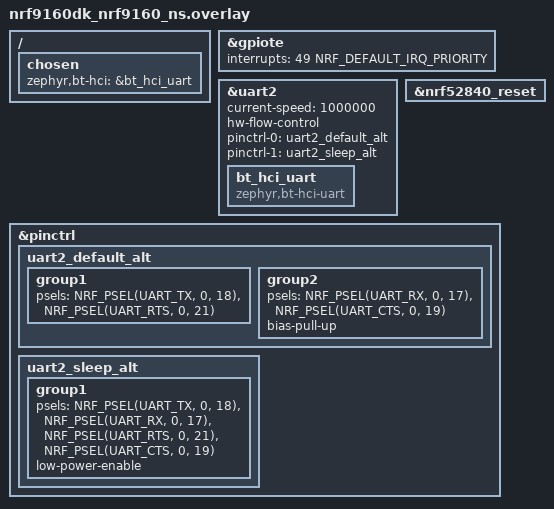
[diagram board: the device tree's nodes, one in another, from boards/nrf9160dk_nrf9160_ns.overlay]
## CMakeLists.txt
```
#
# Copyright (c) 2022 Nordic Semiconductor ASA
#
# SPDX-License-Identifier: LicenseRef-Nordic-5-Clause
#

cmake_minimum_required(VERSION 3.20.0)

find_package(Zephyr REQUIRED HINTS $ENV{ZEPHYR_BASE})
project(nrf_cloud_multi_service)

# Include certs files if enabled.
zephyr_include_directories_ifdef(CONFIG_NRF_CLOUD_PROVISION_CERTIFICATES certs)

# NORDIC SDK APP START
target_sources(app PRIVATE src/main.c)
target_sources(app PRIVATE src/application.c)
target_sources(app PRIVATE src/cloud_connection.c)
target_sources(app PRIVATE src/message_queue.c)
target_sources(app PRIVATE src/temperature.c)
target_sources(app PRIVATE src/fota_support.c)
target_sources(app PRIVATE src/led_control.c)
target_sources(app PRIVATE src/sample_reboot.c)
target_sources(app PRIVATE src/shadow_config.c)

if(CONFIG_LOCATION_TRACKING)
  target_sources(app PRIVATE src/location_tracking.c)
endif()

if(CONFIG_COAP_SHADOW)
  target_sources(app PRIVATE src/shadow_support_coap.c)
endif()

if(CONFIG_COAP_FOTA)
  target_sources(app PRIVATE src/fota_support_coap.c)
endif()

if(CONFIG_NRF_PROVISIONING)
  target_sources(app PRIVATE src/provisioning_support.c)
endif()

# Include modem-specific features if supported
if(CONFIG_NRF_MODEM_LIB)
  target_sources(app PRIVATE src/at_commands.c)
endif()

# NORDIC SDK APP END

zephyr_include_directories(src)
```

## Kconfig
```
#
# Copyright (c) 2022 Nordic Semiconductor ASA
#
# SPDX-License-Identifier: LicenseRef-Nordic-5-Clause
#

menu "Multi Service Sample Settings"

config APP_VERSION
	string "Multi Service Sample version"
	default "1.0.0"

config CLOUD_CONNECTION_RETRY_TIMEOUT_SECONDS
	int "Cloud connection retry timeout (seconds)"
	default 30
	help
	  If connecting to nRF Cloud takes longer than this timeout, it will be
	  reattempted.

config CLOUD_READY_TIMEOUT_SECONDS
	int "Cloud readiness timeout (seconds)"
	default 600
	help
	  If the connection to nRF Cloud does not become ready within this
	  timeout, the sample will reset its connection and try again.

config DATE_TIME_ESTABLISHMENT_TIMEOUT_SECONDS
	int "Modem date and time establishment timeout (seconds)"
	default 300
	help
	  The sample will wait this many seconds for the modem to determine the
	  current date and time before giving up and moving on.

config APPLICATION_THREAD_STACK_SIZE
	int "Application Thread Stack Size (bytes)"
	default 2048
	help
	  Sets the stack size (in bytes) for the application thread of the
	  sample.

config CONNECTION_THREAD_STACK_SIZE
	int "Connection Thread Stack Size (bytes)"
	default 2048
	help
	  Sets the stack size (in bytes) for the connection thread of the
	  sample.

config MESSAGE_THREAD_STACK_SIZE
	int "Message Queue Thread Stack Size (bytes)"
	default 2048
	help
	  Sets the stack size (in bytes) for the message queue processing
	  thread of the sample.

config LED_THREAD_STACK_SIZE
	int "LED Thread Stack Size (bytes)"
	default 1024
	help
	  Sets the stack size (in bytes) for the LED thread.

config MAX_OUTGOING_MESSAGES
	int "Outgoing message maximum"
	default 25
	help
	  Sets the maximum number of device messages which may be enqueued
	  before further messages are dropped.
	  Increasing this value may require an increase to CONFIG_HEAP_MEM_POOL_SIZE.

config MAX_CONSECUTIVE_SEND_FAILURES
	int "Max outgoing consecutive send failures"
	default 5
	help
	  Sets the maximum number of device messages which may fail to send
	  before a connection reset and cooldown is triggered.

config CONSECUTIVE_SEND_FAILURE_COOLDOWN_SECONDS
	int "Cooldown after max consecutive send failures exceeded"
	default 10
	help
	  If a connection reset is triggered by too many failed device
	  messages, the sample will wait this long (in seconds) before trying
	  again.

config SENSOR_SAMPLE_INTERVAL_SECONDS
	int "Sensor sampling interval (seconds)"
	default 60
	help
	  Sets the time to wait between each sensor sample.

menuconfig LOCATION_TRACKING
	bool "Location tracking service"
	default y
	help
	  Uses GNSS, LTE, and/or Wi-Fi information to determine and report device
	  location.

if LOCATION_TRACKING

config LOCATION_TRACKING_SAMPLE_INTERVAL_SECONDS
	int "Location sampling interval (seconds)"
	default 60
	help
	  Sets the location sampling interval in seconds.

config LOCATION_TRACKING_GNSS
	bool "Use GNSS method for location tracking"
	default y
	depends on LOCATION_METHOD_GNSS
	help
	  Disable all location tracking methods to completely disable location tracking.

config LOCATION_TRACKING_CELLULAR
	bool "Use cellular method for location tracking"
	default y
	depends on LOCATION_METHOD_CELLULAR
	help
	  Disable all location tracking methods to completely disable location tracking.

config LOCATION_TRACKING_WIFI
	bool "Use Wi-Fi method for location tracking"
	depends on LOCATION_METHOD_WIFI
	help
	  Requires the use of an nRF7002 companion chip.
	  Disable all location tracking methods to completely disable location tracking.

endif

config TEMP_DATA_USE_SENSOR
	bool "Use genuine temperature data"
	depends on BOARD_THINGY91_NRF9160_NS || BOARD_THINGY91X_NRF9151_NS
	default y if BOARD_THINGY91_NRF9160_NS || BOARD_THINGY91X_NRF9151_NS
	select SENSOR
	select BME680
	help
	  Sets whether to take genuine temperature measurements from a
	  connected BME680 sensor, or just simulate sensor data.

config TEMP_TRACKING
	bool "Track temperature"
	default y
	help
	  Sets whether to take temperature measurements.

config TEMP_ALERT_LIMIT
	int "Temperature limit to print alert"
	default 30
	help
	  Sets the temperature in degrees C over which a temperature alert will
	  be printed through serial terminal.

choice
	prompt "LED indication"
	default LED_INDICATION_PWM if BOARD_THINGY91_NRF9160_NS || BOARD_THINGY91X_NRF9151_NS
	default LED_INDICATION_GPIO if BOARD_NRF9160DK_NRF9160_NS || BOARD_NRF9161DK_NRF9161_NS || $(dt_compat_enabled,gpio-leds)
	default LED_INDICATION_DISABLED

config LED_INDICATION_PWM
	bool "Enable LED indication using the pwm-leds driver"
	select LED
	select LED_PWM
	select PWM

config LED_INDICATION_GPIO
	bool "Enable LED indication using the gpio-leds driver"
	select LED
	select LED_GPIO

config LED_INDICATION_DISABLED
	bool "Disable LED indication"

endchoice

choice
	prompt "LED indication LED type"
	depends on !LED_INDICATION_DISABLED
	default LED_INDICATOR_RGB if (BOARD_THINGY91_NRF9160_NS || BOARD_THINGY91X_NRF9151_NS) && LED_INDICATION_PWM
	default LED_INDICATOR_4LED if !LED_INDICATION_DISABLED
	default LED_INDICATOR_NONE

config LED_INDICATOR_RGB
	bool "A single RGB LED"
	depends on LED_INDICATION_PWM

config LED_INDICATOR_4LED
	bool "Four binary LEDs"
	depends on !LED_INDICATION_DISABLED

config LED_INDICATOR_NONE
	bool "No indicator LEDs"
	depends on LED_INDICATION_DISABLED

endchoice

config LED_VERBOSE_INDICATION
	bool "Enables extra LED status indications"
	depends on !LED_INDICATION_DISABLED
	default y

config LED_CONTINUOUS_INDICATION
	bool "Show an idle pattern instead of turning LEDs off"
	depends on !LED_INDICATION_DISABLED
	default y

config GNSS_FIX_TIMEOUT_SECONDS
	int "GNSS Fix timeout"
	default 40
	help
	  On each location sample, try for this long to achieve a GNSS fix
	  before falling back to cellular positioning.
	  Set this to 20 or so seconds below the sensor sample interval so
	  that there is time left over to perform cellular positioning.
	  Otherwise, location samples may occur at a longer interval than
	  requested.

config TEST_COUNTER
	bool "Sets whether the test counter is enabled"
	help
	  When enabled, the test counter configuration setting in the shadow is ignored.

config TEST_COUNTER_MULTIPLIER
	int "The number of test counter messages sent on each update"
	default 1
	range 1 1000
	help
	  This is a way to increase the number of device messages sent by the sample.
	  It is useful for load testing.

config AT_CMD_REQUESTS
	bool "Enables remote execution of AT commands using device messages"
	depends on !NRF_CLOUD_COAP
	default y

config AT_CMD_REQUEST_RESPONSE_BUFFER_LENGTH
	int "Max length (in bytes) for Modem responses during AT command requests"
	help
	  Responses to modem AT commands are stored in a buffer of this length before being sent to
	  nRF Cloud. If a response from the modem exceeds this length, it will be dropped, and an
	  error code sent in its place (-NRF_E2BIG). Cannot be less than 40 bytes.
	default 200

config POST_PROVISIONING_INTERVAL_M
	int "Delay in minutes between provisioning checks once connected"
	default 30
	help
	  Use a slower rate to check for provisioning after we have successfully connected.
	  Until then use CONFIG_NRF_PROVISIONING_INTERVAL_S.

if NRF_CLOUD_COAP

menuconfig COAP_FOTA
	bool "FOTA service when using CoAP to connect to nRF Cloud"
	select FOTA_DOWNLOAD
	select FOTA_DOWNLOAD_PROGRESS_EVT
	select IMG_ERASE_PROGRESSIVELY
	select DFU_TARGET
	select DOWNLOADER
	select REBOOT
	select CJSON_LIB
	select SETTINGS
	default y

if COAP_FOTA

config COAP_FOTA_JOB_CHECK_RATE_MINUTES
	int "FOTA job check interval (minutes)"
	default 60
	help
	  Sets the time to wait between each request to get any pending FOTA job.

config COAP_FOTA_THREAD_STACK_SIZE
	int "CoAP FOTA Thread Stack Size (bytes)"
	default 2048
	help
	  Sets the stack size (in bytes) for the CoAP FOTA thread of the
	  sample.

endif

menuconfig COAP_SHADOW
	bool "Updating shadow service"
	default y
	help
	  Updates the shadow with device information. Checks for a shadow
	  delta periodically and processes it if received.

if COAP_SHADOW

config COAP_SHADOW_CHECK_RATE_SECONDS
	int "Shadow job check interval (seconds)"
	default 300
	help
	  Sets the time to wait between each request to get any change to the
	  device shadow.

config COAP_SHADOW_THREAD_STACK_SIZE
	int "CoAP Shadow Thread Stack Size (bytes)"
	default 3072
	help
	  Sets the stack size (in bytes) for the CoAP shadow thread of the
	  sample.

endif

config COAP_SEND_CONFIRMABLE
	bool "Send device messages as confirmable"
	help
	  Ensures all CoAP transfers, even for often less important messages such
	  as sensor data, are sent as confirmable messages.

endif

endmenu

if NRF_CLOUD_MQTT
module-str = MQTT Multi Service
endif
if NRF_CLOUD_COAP
module-str = CoAP Multi Service
endif
module = MULTI_SERVICE
source "$(ZEPHYR_BASE)/subsys/logging/Kconfig.template.log_config"

menu "Zephyr Kernel"
source "Kconfig.zephyr"
endmenu
```

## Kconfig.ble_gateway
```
#
# Copyright (c) 2024 Nordic Semiconductor ASA
#
# SPDX-License-Identifier: LicenseRef-Nordic-5-Clause
#

menu "nRF Cloud BLE Gateway Sample Settings"

if NRF_CLOUD_GATEWAY

config USE_BT_HCI_SETUP
	bool "Use BT HCI setup"
	default y
	select BT_HCI_SETUP
	help
	  Get the setup to run.

config APPLICATION_WORKQUEUE_PRIORITY
	int "Application workqueue priority"
	default SYSTEM_WORKQUEUE_PRIORITY

config FLASH_TEST
	bool "Enable Flash Test module"
	default n
	select NRFX_SPIM if FLASH_TEST
	select NRFX_SPIM3 if FLASH_TEST
	select SPI if FLASH_TEST
	select SPI_NOR if FLASH_TEST
	help
	  Enable to test Erase, Write, and Read of external flash.

config CLOUD_BUTTON
	bool "Enable button sensor"
	default y

config CLOUD_BUTTON_INPUT
	int "Set button sensor button number"
	range 1 4 if BOARD_NRF9160_PCA10090NS
	range 1 1 if BOARD_NRF9160_PCA20035NS
	default 1

config ENTER_52840_MCUBOOT_VIA_BUTTON
	bool "Button enables 52840 MCUboot"
	depends on BOARD_APRICITY_GATEWAY_NRF9160 || BOARD_APRICITY_GATEWAY_NRF9160_NS
	help
	  Holding a button during and after startup will place the
	  nrf52840 into MCUboot mode so the firmware can be updated.

config SHELL_PROMPT_SECURE
	string "Displayed prompt name"
	default "uart:~# "
	help
	  Displayed prompt name for UART backend once user has logged in.

config SHELL_DEFAULT_PASSWORD
	string "Factory-set initial password"
	default "nordic"
	help
	  User needs to type this to enter the shell and execute
	  commands.

config GATEWAY_BLE_FOTA
	bool "Enable BLE FOTA support"
	default y
	help
	  Enable ability to receive FOTA jobs for specific BLE devices,
	  then inject data from one or more file downloads to a BLE
	  device that supports a compatible DFU protocol.

config GATEWAY_DBG_CMDS
	bool "Enable debugging commands"
	default y
	select CPU_LOAD
	select CPU_LOAD_CMDS
	select KERNEL_SHELL

config GATEWAY_SHELL
	bool "Enable shell for administering nRF Cloud gateway"
	default y
	select SHELL
	select SHELL_CMDS
	select SHELL_HISTORY
	select SHELL_METAKEYS
	select SHELL_VT100_COLORS
	select SHELL_BACKEND_SERIAL
	select SHELL_CMDS_SELECT

config STARTING_LOG_OVERRIDE
	bool "Different logging level at boot"
	default n
	help
	  All configured logging will occur if disabled. Otherwise,
	  logging changed to STARTING_LOG_LEVEL until user logs in and
	  manually enables with 'log enable inf' (or whatever level is
	  desired).

choice
	prompt "Max compiled-in log level to boot with"
	default STARTING_LOG_LEVEL_INF
	depends on LOG

config STARTING_LOG_LEVEL_OFF
	bool "Off"

config STARTING_LOG_LEVEL_ERR
	bool "Error"

config STARTING_LOG_LEVEL_WRN
	bool "Warning"

config STARTING_LOG_LEVEL_INF
	bool "Info"

config STARTING_LOG_LEVEL_DBG
	bool "Debug"

endchoice

config STARTING_LOG_LEVEL
	int
	depends on LOG
	default 0 if STARTING_LOG_LEVEL_OFF
	default 1 if STARTING_LOG_LEVEL_ERR
	default 2 if STARTING_LOG_LEVEL_WRN
	default 3 if STARTING_LOG_LEVEL_INF
	default 4 if STARTING_LOG_LEVEL_DBG

if NRF_CLOUD_MQTT
module-str = MQTT BLE Gateway
endif
if NRF_CLOUD_COAP
module-str = CoAP BLE Gateway
endif
module = NRFCLOUD_BLE_GATEWAY
source "subsys/logging/Kconfig.template.log_config"

endif

endmenu
```

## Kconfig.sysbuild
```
#
# Copyright (c) 2024 Nordic Semiconductor
#
# SPDX-License-Identifier: LicenseRef-Nordic-5-Clause
#

config WIFI_NRF70
	default y if BOARD_THINGY91X_NRF9151_NS

source "${ZEPHYR_BASE}/share/sysbuild/Kconfig"
```

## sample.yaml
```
sample:
  name: nRF Cloud Multi Service Sample
tests:
  sample.cellular.nrf_cloud_multi_service.mqtt:
    sysbuild: true
    build_only: true
    platform_allow:
      - nrf9151dk/nrf9151/ns
      - nrf9160dk/nrf9160/ns
      - nrf9161dk/nrf9161/ns
      - thingy91/nrf9160/ns
      - thingy91x/nrf9151/ns
    integration_platforms:
      - nrf9151dk/nrf9151/ns
      - nrf9160dk/nrf9160/ns
      - thingy91/nrf9160/ns
      - thingy91x/nrf9151/ns
    tags:
      - ci_build
      - sysbuild
      - ci_samples_cellular
  sample.cellular.nrf_cloud_multi_service.mqtt.full:
    sysbuild: true
    build_only: true
    platform_allow: nrf9160dk/nrf9160/ns
    integration_platforms:
      - nrf9160dk/nrf9160/ns
    extra_args:
      - "EXTRA_CONF_FILE=\"overlay_full_modem_fota.conf;overlay_pgps_ext_flash.conf;overlay_mcuboot_ext_flash.conf\""
    tags:
      - ci_build
      - sysbuild
      - ci_samples_cellular
  sample.cellular.nrf_cloud_multi_service.mqtt.min:
    sysbuild: true
    build_only: true
    platform_allow: nrf9160dk/nrf9160/ns
    integration_platforms:
      - nrf9160dk/nrf9160/ns
    extra_args: EXTRA_CONF_FILE="overlay_min_mqtt.conf"
    tags:
      - ci_build
      - sysbuild
      - ci_samples_cellular
  sample.cellular.nrf_cloud_multi_service.coap:
    sysbuild: true
    build_only: true
    platform_allow:
      - nrf9151dk/nrf9151/ns
      - nrf9160dk/nrf9160/ns
      - nrf9161dk/nrf9161/ns
      - thingy91/nrf9160/ns
      - thingy91x/nrf9151/ns
    integration_platforms:
      - nrf9151dk/nrf9151/ns
      - nrf9160dk/nrf9160/ns
      - nrf9161dk/nrf9161/ns
      - thingy91x/nrf9151/ns
    extra_args: EXTRA_CONF_FILE="overlay_coap.conf"
    tags:
      - ci_build
      - sysbuild
      - ci_samples_cellular
  sample.cellular.nrf_cloud_multi_service.coap.min:
    sysbuild: true
    build_only: true
    platform_allow: nrf9160dk/nrf9160/ns
    integration_platforms:
      - nrf9160dk/nrf9160/ns
    extra_args: EXTRA_CONF_FILE="overlay_coap.conf;overlay_min_coap.conf"
    tags:
      - ci_build
      - sysbuild
      - ci_samples_cellular
  sample.cellular.nrf_cloud_multi_service.coap.trace:
    sysbuild: true
    build_only: true
    platform_allow:
      - nrf9151dk/nrf9151/ns
      - nrf9160dk/nrf9160/ns
      - nrf9161dk/nrf9161/ns
    integration_platforms:
      - nrf9151dk/nrf9151/ns
      - nrf9160dk/nrf9160/ns
      - nrf9161dk/nrf9161/ns
    extra_args:
      - EXTRA_CONF_FILE="overlay-coap_nrf_provisioning.conf;overlay_coap.conf"
      - nrf_cloud_multi_service_SNIPPET=nrf91-modem-trace-uart
    tags:
      - ci_build
      - sysbuild
      - ci_samples_cellular
  sample.cellular.nrf_cloud_multi_service.mqtt.provisioning.trace:
    sysbuild: true
    build_only: true
    platform_allow:
      - nrf9151dk/nrf9151/ns
      - nrf9160dk/nrf9160/ns
      - nrf9161dk/nrf9161/ns
      - thingy91/nrf9160/ns
      - thingy91x/nrf9151/ns
    integration_platforms:
      - nrf9151dk/nrf9151/ns
      - nrf9160dk/nrf9160/ns
      - nrf9161dk/nrf9161/ns
      - thingy91/nrf9160/ns
      - thingy91x/nrf9151/ns
    extra_args:
      - EXTRA_CONF_FILE="overlay-http_nrf_provisioning.conf"
      - nrf_cloud_multi_service_SNIPPET=nrf91-modem-trace-uart
    tags:
      - ci_build
      - sysbuild
      - ci_samples_cellular
  sample.cellular.nrf7002ek_wifi.scan:
    sysbuild: true
    build_only: true
    integration_platforms:
      - nrf9151dk/nrf9151/ns
      - nrf9161dk/nrf9161/ns
    platform_allow:
      - nrf9151dk/nrf9151/ns
      - nrf9160dk/nrf9160/ns
      - nrf9161dk/nrf9161/ns
    extra_args:
      - nrf_cloud_multi_service_SHIELD=nrf7002ek_nrf7000
      - EXTRA_CONF_FILE="overlay-nrf7002ek-wifi-scan-only.conf"
      - SB_CONF_FILE="sysbuild_nrf700x-wifi-scan.conf"
    tags:
      - ci_build
      - sysbuild
      - ci_samples_cellular
  sample.cellular.nrf7002ek_wifi.conn:
    sysbuild: true
    build_only: true
    integration_platforms:
      - nrf5340dk/nrf5340/cpuapp/ns
    platform_allow: nrf5340dk/nrf5340/cpuapp/ns
    extra_args:
      - nrf_cloud_multi_service_SHIELD=nrf7002ek
      - EXTRA_CONF_FILE="overlay_nrf700x_wifi_mqtt_no_lte.conf"
      - SB_CONF_FILE="sysbuild_nrf700x-wifi-conn.conf"
    tags:
      - ci_build
      - sysbuild
      - ci_samples_cellular
  sample.cellular.nrf7002dk_wifi.conn.mqtt:
    sysbuild: true
    build_only: true
    integration_platforms:
      - nrf7002dk/nrf5340/cpuapp/ns
    platform_allow: nrf7002dk/nrf5340/cpuapp/ns
    extra_args:
      - EXTRA_CONF_FILE="overlay_nrf700x_wifi_mqtt_no_lte.conf"
      - SB_CONF_FILE="sysbuild_nrf700x-wifi-conn.conf"
    tags:
      - ci_build
      - sysbuild
      - ci_samples_cellular
  sample.cellular.nrf7002dk_wifi.conn.coap:
    sysbuild: true
    build_only: true
    integration_platforms:
      - nrf7002dk/nrf5340/cpuapp/ns
    platform_allow: nrf7002dk/nrf5340/cpuapp/ns
    extra_args:
      - EXTRA_CONF_FILE="overlay_nrf700x_wifi_coap_no_lte.conf"
      - SB_CONF_FILE="sysbuild_nrf700x-wifi-conn.conf"
    tags:
      - ci_build
      - sysbuild
      - ci_samples_cellular
```

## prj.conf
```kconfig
#
# Copyright (c) 2022 Nordic Semiconductor ASA
#
# SPDX-License-Identifier: LicenseRef-Nordic-5-Clause
#

# TF-M config
CONFIG_TFM_PROFILE_TYPE_MINIMAL=y

# Log level
# For more verbose and detailed log output, set the log level to
# CONFIG_MULTI_SERVICE_LOG_LEVEL_DBG=y instead.
CONFIG_MULTI_SERVICE_LOG_LEVEL_INF=y

# General config
CONFIG_EVENTS=y
CONFIG_PICOLIBC_IO_FLOAT=y
CONFIG_RESET_ON_FATAL_ERROR=y
CONFIG_NCS_SAMPLES_DEFAULTS=y
CONFIG_DK_LIBRARY=y

# LED indication
# Uncomment these to minimize LED state indication when power savings are necessary
# CONFIG_LED_VERBOSE_INDICATION=n
# CONFIG_LED_CONTINUOUS_INDICATION=n

# Or, uncomment this to completely disable LED state indication
# CONFIG_LED_INDICATION_DISABLED=y

# Improved Logging
# CONFIG_LOG_MODE_DEFERRED allows logging from multiple threads simultaneously without creating
# splintered log entries, at the cost of needing a buffer for storing logs.
CONFIG_LOG_MODE_DEFERRED=y

# CONFIG_LOG_BUFFER_SIZE is the aforementioned buffer. A size of 4096 bytes is useful for debugging
# and prototyping, but is probably more than necessary for production-ready firmware.
CONFIG_LOG_BUFFER_SIZE=4096

# Heap and stacks
# Extended AT host/monitor stack/heap sizes since some nrf_cloud credentials are longer than 1024 bytes.
CONFIG_AT_MONITOR_HEAP_SIZE=2048
CONFIG_AT_HOST_STACK_SIZE=2048
# Extended memory heap size needed both for PGPS and for encoding JSON-based nRF Cloud Device Messages.
CONFIG_HEAP_MEM_POOL_SIZE=19000
CONFIG_SYSTEM_WORKQUEUE_STACK_SIZE=4096
# The default modem shared memory buffer for TX is significantly larger than required.
# RX buffer has to be larger because the sample reads certificates so using default value.
CONFIG_NRF_MODEM_LIB_SHMEM_TX_SIZE=4096

# Enable Networking and Connection Manager.
CONFIG_NETWORKING=y
CONFIG_NET_SOCKETS=y
CONFIG_NET_SOCKETS_OFFLOAD=y
CONFIG_NET_MGMT_EVENT_STACK_SIZE=2048
CONFIG_NET_CONNECTION_MANAGER_MONITOR_STACK_SIZE=1024
CONFIG_MAIN_STACK_SIZE=2048

# Enable LTE Connectivity using Connection Manager
CONFIG_NET_IPV4=y
CONFIG_NET_IPV6=y
CONFIG_NET_IPV6_NBR_CACHE=n
CONFIG_NET_IPV6_MLD=n
CONFIG_NET_CONNECTION_MANAGER=y
CONFIG_NRF_MODEM_LIB_NET_IF=y
CONFIG_NRF_MODEM_LIB_NET_IF_AUTO_DOWN=y
CONFIG_NRF_MODEM_LIB_NET_IF_DOWN_DEFAULT_LTE_DISCONNECT=y

# Enable power savings mode
CONFIG_LTE_PSM_REQ=y
# Set the PSM Requested Active Time to 20 seconds
CONFIG_LTE_PSM_REQ_RAT="00001010"

# Modem library
CONFIG_NRF_MODEM_LIB=y

# AT commands interface
CONFIG_UART_INTERRUPT_DRIVEN=y
CONFIG_AT_HOST_LIBRARY=y

# Wait for credential installation to be complete before connecting to nRF Cloud
CONFIG_NRF_CLOUD_CHECK_CREDENTIALS=y

# nRF Cloud
CONFIG_NRF_CLOUD=y
CONFIG_NRF_CLOUD_MQTT=y # This also enables FOTA by implicitly setting CONFIG_NRF_CLOUD_FOTA=y

# MQTT
CONFIG_MQTT_KEEPALIVE=120

# MCUBOOT - Needed by FOTA
CONFIG_BOOTLOADER_MCUBOOT=y
CONFIG_IMG_MANAGER=y
CONFIG_MCUBOOT_IMG_MANAGER=y
CONFIG_STREAM_FLASH_ERASE=y

# Location Services configuration
CONFIG_LOCATION=y
CONFIG_LOCATION_METHOD_GNSS=y
CONFIG_LOCATION_METHOD_CELLULAR=y
CONFIG_NRF_CLOUD_AGNSS=y
CONFIG_NRF_CLOUD_LOCATION=y
CONFIG_MODEM_INFO=y
CONFIG_MODEM_INFO_ADD_NETWORK=y
CONFIG_NRF_CLOUD_PGPS=y
CONFIG_NRF_CLOUD_PGPS_REPLACEMENT_THRESHOLD=4
CONFIG_NRF_CLOUD_PGPS_REQUEST_UPON_INIT=y

# Date Time lib - Used by PGPS and main application
CONFIG_DATE_TIME=y

# LTE link control - used by PGPS and main application
CONFIG_LTE_LINK_CONTROL=y
CONFIG_LTE_LC_EDRX_MODULE=y
CONFIG_LTE_LC_PSM_MODULE=y

# Settings - used by nRF Cloud library and PGPS
CONFIG_SETTINGS=y
CONFIG_SETTINGS_FCB=y
CONFIG_FCB=y

# Download Client - used by FOTA and PGPS
CONFIG_DOWNLOADER=y
CONFIG_DOWNLOADER_STACK_SIZE=4352
CONFIG_DOWNLOADER_MAX_HOSTNAME_SIZE=128

# Flash - Used by FOTA and PGPS
CONFIG_FLASH=y
CONFIG_FLASH_PAGE_LAYOUT=y
CONFIG_FLASH_MAP=y
CONFIG_STREAM_FLASH=y
CONFIG_MPU_ALLOW_FLASH_WRITE=y
CONFIG_PM_EXTERNAL_FLASH_MCUBOOT_SECONDARY=n
CONFIG_NRF_CLOUD_LOG_DIRECT=y
CONFIG_NRF_CLOUD_LOG_OUTPUT_LEVEL=3

# On initial connection to the cloud, add info sections to the shadow
CONFIG_NRF_CLOUD_SEND_DEVICE_STATUS=y
CONFIG_NRF_CLOUD_SEND_DEVICE_STATUS_NETWORK=y
CONFIG_NRF_CLOUD_SEND_DEVICE_STATUS_SIM=y
CONFIG_NRF_CLOUD_SEND_SERVICE_INFO_FOTA=y
```

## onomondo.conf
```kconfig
### Onomondo SoftSIM ###
CONFIG_SOFTSIM_DEBUG=n
CONFIG_SOFTSIM_LOG_LEVEL_INF=y
CONFIG_SOFTSIM_BUNDLE_TEMPLATE_HEX=y
### Onomondo SoftSIM ###

# Configured to allow a reboot following the provisioning of a profile
CONFIG_REBOOT=y

# Reduce the size of TF-M by disabling the PS
CONFIG_TFM_PARTITION_PROTECTED_STORAGE=n
CONFIG_PSA_CRYPTO_DRIVER_CC3XX=n

# Reduce the size of the TF-M partition
# when combined with static partitioning
CONFIG_PM_PARTITION_SIZE_TFM=0x10000

# The bootloader adds a small mcuboot_pad partition,
# whose size must be subtracted from the TF-M partition
#CONFIG_BOOTLOADER_MCUBOOT=y
#CONFIG_PM_PARTITION_SIZE_TFM=0xfe00

# From modules/lib/onomondo-softsim/overlay-softsim.conf
### Onomondo SoftSIM ###
# Onomondo SoftSIM Configurations
CONFIG_SOFTSIM=y
CONFIG_SOFTSIM_AUTO_INIT=y

# NVS Configurations
CONFIG_NVS=y
CONFIG_NVS_LOG_LEVEL_ERR=y
CONFIG_PM_PARTITION_SIZE_NVS_STORAGE=0x8000

# Flash Configurations
CONFIG_FLASH=y
CONFIG_FLASH_MAP=y
CONFIG_FLASH_PAGE_LAYOUT=y
CONFIG_MPU_ALLOW_FLASH_WRITE=y

# Stack and Heap Configurations
CONFIG_MAIN_STACK_SIZE=5000
CONFIG_HEAP_MEM_POOL_SIZE=30000

# TF-M Configurations
CONFIG_BUILD_WITH_TFM=y
CONFIG_TFM_PROFILE_TYPE_NOT_SET=y
CONFIG_TFM_LOG_LEVEL_SILENCE=y

# PSA Crypto Configurations
CONFIG_PSA_WANT_ALG_CBC_NO_PADDING=y
CONFIG_PSA_WANT_ALG_ECB_NO_PADDING=y
CONFIG_PSA_WANT_ALG_CMAC=y
CONFIG_PSA_WANT_KEY_TYPE_AES=y

# Libraries
CONFIG_NEWLIB_LIBC=y
CONFIG_FP_SOFTABI=y
```

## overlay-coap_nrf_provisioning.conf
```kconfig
#
# Copyright (c) 2024 Nordic Semiconductor ASA
#
# SPDX-License-Identifier: LicenseRef-Nordic-5-Clause
#

# Enable provisioning library/provisioning shell dependencies
CONFIG_MODEM_JWT=y
CONFIG_MODEM_ATTEST_TOKEN=y

# Enable the provisioning library
CONFIG_NRF_PROVISIONING=y
CONFIG_NRF_PROVISIONING_COAP=y
CONFIG_NRF_PROVISIONING_SCHEDULED=y
CONFIG_NRF_PROVISIONING_AUTO_START_ON_INIT=y

# Enable provisioning shell
CONFIG_SHELL=y
CONFIG_NRF_PROVISIONING_SHELL=y

# Adjust shell buffer sizes to handle nRF Cloud certs
CONFIG_SHELL_BACKEND_SERIAL_RX_RING_BUFFER_SIZE=4096
CONFIG_SHELL_CMD_BUFF_SIZE=4096
CONFIG_SHELL_BACKEND_SERIAL_API_INTERRUPT_DRIVEN=y

# Disable AT host and switch to using shell
CONFIG_AT_HOST_LIBRARY=n
CONFIG_AT_SHELL=y
CONFIG_SHELL_WILDCARD=n

# Configure provisioning message formatting
CONFIG_NRF_PROVISIONING_CODEC=y
CONFIG_NRF_PROVISIONING_CBOR=y
CONFIG_ZCBOR=y

# Include provisioning service certificate as part of the binary.
# Used only if none has been provisioned
CONFIG_NRF_PROVISIONING_WITH_CERT=y
CONFIG_NRF_PROVISIONING_ROOT_CA_SEC_TAG=42
CONFIG_NRF_CLOUD_CLIENT_ID_SRC_INTERNAL_UUID=y

# Max provisioning commands per response
CONFIG_NRF_PROVISIONING_CBOR_RECORDS=10

# Set the provisioning interval to 60 seconds.
# This is a very frequent interval. To save power, set this to something approaching 24 hours.
# But note that provisioning may take up to twice as long as this interval, since it
# happens in two steps.
CONFIG_NRF_PROVISIONING_INTERVAL_S=60

# Request spread factor
CONFIG_NRF_PROVISIONING_SPREAD_S=5

# Adjust provisioning and buffer sizes to handle nRF Cloud certs
CONFIG_NRF_PROVISIONING_RX_BUF_SZ=4096
CONFIG_NRF_PROVISIONING_TX_BUF_SZ=4096
CONFIG_NRF_PROVISIONING_CODEC_AT_CMD_LEN=2048
CONFIG_NRF_PROVISIONING_CODEC_RX_SZ_START=2048

# CoAP Client
CONFIG_COAP_EXTENDED_OPTIONS_LEN_VALUE=192
CONFIG_COAP_CLIENT_THREAD_PRIORITY=0
CONFIG_COAP_CLIENT_BLOCK_SIZE=1024
CONFIG_COAP_CLIENT_MESSAGE_SIZE=1024
CONFIG_COAP_CLIENT_STACK_SIZE=6144
```

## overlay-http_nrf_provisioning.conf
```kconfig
#
# Copyright (c) 2023 Nordic Semiconductor ASA
#
# SPDX-License-Identifier: LicenseRef-Nordic-5-Clause
#

# Enable provisioning library/provisioning shell dependencies
CONFIG_MODEM_JWT=y
CONFIG_MODEM_ATTEST_TOKEN=y

# Enable the provisioning library
CONFIG_NRF_PROVISIONING=y
CONFIG_NRF_PROVISIONING_HTTP=y
CONFIG_NRF_PROVISIONING_SCHEDULED=y
CONFIG_NRF_PROVISIONING_AUTO_START_ON_INIT=y

# Enable provisioning shell
CONFIG_SHELL=y
CONFIG_NRF_PROVISIONING_SHELL=y

# Adjust shell buffer sizes to handle nRF Cloud certs
CONFIG_SHELL_BACKEND_SERIAL_RX_RING_BUFFER_SIZE=4096
CONFIG_SHELL_CMD_BUFF_SIZE=4096

# Disable AT host and switch to using shell
CONFIG_AT_HOST_LIBRARY=n
CONFIG_AT_SHELL=y
CONFIG_SHELL_WILDCARD=n

# Configure provisioning message formatting
CONFIG_NRF_PROVISIONING_CODEC=y
CONFIG_NRF_PROVISIONING_CBOR=y
CONFIG_ZCBOR=y
CONFIG_ZCBOR_CANONICAL=y

# Include provisioning service certificate as part of the binary.
# Used only if none has been provisioned
CONFIG_NRF_PROVISIONING_WITH_CERT=y
CONFIG_NRF_PROVISIONING_ROOT_CA_SEC_TAG=50
CONFIG_NRF_CLOUD_CLIENT_ID_SRC_INTERNAL_UUID=y

# Max provisioning commands per response
CONFIG_NRF_PROVISIONING_CBOR_RECORDS=10

# Set the provisioning interval to 60 seconds.
# This is a very frequent interval. To save power, set this to something approaching 24 hours.
# But note that provisioning may take up to twice as long as this interval, since it
# happens in two steps.
CONFIG_NRF_PROVISIONING_INTERVAL_S=60

# Request spread factor
CONFIG_NRF_PROVISIONING_SPREAD_S=5

# Adjust provisioning and buffer sizes to handle nRF Cloud certs
CONFIG_NRF_PROVISIONING_RX_BUF_SZ=4096
CONFIG_NRF_PROVISIONING_TX_BUF_SZ=4096
CONFIG_NRF_PROVISIONING_CODEC_AT_CMD_LEN=2048
CONFIG_NRF_PROVISIONING_CODEC_RX_SZ_START=2048
```

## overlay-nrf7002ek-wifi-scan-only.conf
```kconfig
#
# Copyright (c) 2022 Nordic Semiconductor ASA
#
# SPDX-License-Identifier: LicenseRef-Nordic-5-Clause
#

# Overlay to use nRF7002 EK on top of nrf9160 DK for Wi-Fi scanning

# Enable the Wi-Fi location method:
CONFIG_LOCATION_TRACKING_WIFI=y
CONFIG_LOCATION_METHOD_WIFI=y
# Align this with CONFIG_NRF_WIFI_SCAN_MAX_BSS_CNT.
# Also see comments for CONFIG_HEAP_MEM_POOL_SIZE.
CONFIG_LOCATION_METHOD_WIFI_SCANNING_RESULTS_MAX_CNT=10

# Enable Wi-Fi drivers
CONFIG_WIFI=y
CONFIG_WIFI_NRF70=y
CONFIG_WIFI_NRF70_SKIP_LOCAL_ADMIN_MAC=y
# Align this with CONFIG_LOCATION_METHOD_WIFI_SCANNING_RESULTS_MAX_CNT.
# Also see comments for CONFIG_HEAP_MEM_POOL_SIZE.
CONFIG_NRF_WIFI_SCAN_MAX_BSS_CNT=10
CONFIG_NET_L2_ETHERNET=y
# We need 2 to ensure nrf9x_socket gets an IP address regardless of order of net_if array
CONFIG_NET_IF_MAX_IPV4_COUNT=2
CONFIG_NET_IF_MAX_IPV6_COUNT=2

# But disable the supplicant, since we don't need connectivity
CONFIG_WIFI_NM_WPA_SUPPLICANT=n
CONFIG_MBEDTLS=n

# Stack/heap tweaks needed to support Wi-Fi.
# Heap allocation should be changed when CONFIG_LOCATION_METHOD_WIFI_SCANNING_RESULTS_MAX_CNT
# and CONFIG_NRF_WIFI_SCAN_MAX_BSS_CNT (which should be the same value) are changed.
CONFIG_NRF_WIFI_CTRL_HEAP_SIZE=20000
CONFIG_HEAP_MEM_POOL_IGNORE_MIN=y
CONFIG_MAIN_STACK_SIZE=2048
CONFIG_NET_MGMT_EVENT_STACK_SIZE=1024

# NET tweaks needed to support Wi-FI
CONFIG_NET_BUF_RX_COUNT=1
CONFIG_NET_BUF_TX_COUNT=1
CONFIG_NET_PKT_RX_COUNT=1
CONFIG_NET_PKT_TX_COUNT=1
CONFIG_NET_TX_STACK_SIZE=512
CONFIG_NET_RX_STACK_SIZE=512
CONFIG_NET_TC_TX_COUNT=1
CONFIG_NET_MAX_CONTEXTS=5

# Disable LED patterns, enabling WiFi scanning takes control of two LEDs
CONFIG_LED_INDICATION_DISABLED=y
```

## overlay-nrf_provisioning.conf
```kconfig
#
# Copyright (c) 2023 Nordic Semiconductor ASA
#
# SPDX-License-Identifier: LicenseRef-Nordic-5-Clause
#

# Enable provisioning library/provisioning shell dependencies
CONFIG_MODEM_JWT=y
CONFIG_MODEM_ATTEST_TOKEN=y

# Enable the provisioning library
CONFIG_NRF_PROVISIONING=y
CONFIG_NRF_PROVISIONING_AUTO_INIT=n
CONFIG_NRF_PROVISIONING_HTTP=y

# Enable provisioning shell
CONFIG_SHELL=y
CONFIG_NRF_PROVISIONING_SHELL=y

# Wait for credential installation to be complete before connecting to nRF Cloud
CONFIG_NRF_CLOUD_CHECK_CREDENTIALS=y

# Adjust shell buffer sizes to handle nRF Cloud certs
CONFIG_SHELL_BACKEND_SERIAL_RX_RING_BUFFER_SIZE=4096
CONFIG_SHELL_CMD_BUFF_SIZE=4096

# Disable AT host and switch to using shell
CONFIG_AT_HOST_LIBRARY=n
CONFIG_AT_SHELL=y
CONFIG_SHELL_WILDCARD=n

# Configure provisioning message formatting
CONFIG_NRF_PROVISIONING_CODEC=y
CONFIG_NRF_PROVISIONING_CBOR=y
CONFIG_ZCBOR=y
CONFIG_ZCBOR_CANONICAL=y

# Include provisioning service certificate as part of the binary.
# Used only if none has been provisioned
CONFIG_NRF_PROVISIONING_WITH_CERT=y
CONFIG_NRF_PROVISIONING_ROOT_CA_SEC_TAG=50

# Max provisioning commands per response
CONFIG_NRF_PROVISIONING_CBOR_RECORDS=20

# Set the provisioning interval to 60 seconds.
# This is a very frequent interval. To save power, set this to something approaching 24 hours.
# But note that provisioning may take up to twice as long as this interval, since it
# happens in two steps.
CONFIG_NRF_PROVISIONING_INTERVAL_S=60

# Request spread factor
CONFIG_NRF_PROVISIONING_SPREAD_S=5

# Adjust provisioning and buffer sizes to handle nRF Cloud certs
CONFIG_NRF_PROVISIONING_RX_BUF_SZ=2048
CONFIG_NRF_PROVISIONING_TX_BUF_SZ=4096
```

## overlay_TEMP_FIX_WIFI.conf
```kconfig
# Some temporary tweaks provided in this PR to help colleagues test on it successfully.

# Fixes heap issues on connect. 160000 is enough to fix known issues, but use 190000 to prevent
# possible unknown additional issues.
CONFIG_HEAP_MEM_POOL_SIZE=190000
CONFIG_COMMON_LIBC_MALLOC_ARENA_SIZE=3808

# Required to prevent stack-overflow when executing wifi_cred auto_connect
CONFIG_SHELL_STACK_SIZE=5500

# Required to prevent stack-overflow during auto connect (if you can manage to get that to work)
CONFIG_NET_CONNECTION_MANAGER_MONITOR_STACK_SIZE=5500
```

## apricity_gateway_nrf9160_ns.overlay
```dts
/*
 * Copyright (c) 2025 Nordic Semiconductor ASA
 *
 * SPDX-License-Identifier: LicenseRef-Nordic-5-Clause
 */

/ {
	chosen {
		zephyr,bt-uart=&uart1;
	};
};
```

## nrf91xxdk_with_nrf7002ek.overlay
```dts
/*
 * Copyright (c) 2022 Nordic Semiconductor ASA
 *
 * SPDX-License-Identifier: LicenseRef-Nordic-5-Clause
 */

/* Disabled because of conflicts on P0.00 and P0.01 - Arduino pins D0 and D1
 * (iovdd-ctrl-gpios and bucken-gpios in nrf7002ek, respectively). */
&uart1 {
	status = "disabled";
};

/* Disabled because the io expander is not being properly enabled, resulting
 * in I2C errors. */
&pcal6408a {
	status = "disabled";
};
```

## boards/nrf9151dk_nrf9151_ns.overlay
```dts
/*
 * Copyright (c) 2024 Nordic Semiconductor ASA
 *
 * SPDX-License-Identifier: LicenseRef-Nordic-5-Clause
 */

/ {
	/* Configure partition manager to use gd25wb256 as the external flash */
	chosen {
		nordic,pm-ext-flash = &gd25wb256;
	};
};

&gd25wb256 {
	status = "okay";
};
```

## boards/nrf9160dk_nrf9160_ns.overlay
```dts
/*
 * Copyright (c) 2024 Nordic Semiconductor ASA
 *
 * SPDX-License-Identifier: LicenseRef-Nordic-5-Clause
 */
/* Use the reset line that is available until v0.14.0 of the DK. */
#include <nrf9160/nrf9160dk_nrf52840_reset_on_if5.dtsi>

/ {
	chosen {
		zephyr,bt-hci=&bt_hci_uart;
	};
};

&gpiote {
	interrupts = <49 NRF_DEFAULT_IRQ_PRIORITY>;
};

&uart2 {
	current-speed = <1000000>;
	status = "okay";
	hw-flow-control;

	pinctrl-0 = <&uart2_default_alt>;
	pinctrl-1 = <&uart2_sleep_alt>;
	pinctrl-names = "default", "sleep";
	bt_hci_uart: bt_hci_uart {
		compatible = "zephyr,bt-hci-uart";
		status = "okay";
	};
};

&nrf52840_reset {
	status = "okay";
};

&pinctrl {
	uart2_default_alt: uart2_default_alt {
		group1 {
			psels = <NRF_PSEL(UART_TX, 0, 18)>,
				<NRF_PSEL(UART_RTS, 0, 21)>;
			};
		group2 {
			psels = <NRF_PSEL(UART_RX, 0, 17)>,
				<NRF_PSEL(UART_CTS, 0, 19)>;
				bias-pull-up;
		};
	};

	uart2_sleep_alt: uart2_sleep_alt {
		group1 {
			psels = <NRF_PSEL(UART_TX, 0, 18)>,
				<NRF_PSEL(UART_RX, 0, 17)>,
				<NRF_PSEL(UART_RTS, 0, 21)>,
				<NRF_PSEL(UART_CTS, 0, 19)>;
			low-power-enable;
		};
	};

};
```

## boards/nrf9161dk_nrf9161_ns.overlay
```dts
/*
 * Copyright (c) 2023 Nordic Semiconductor ASA
 *
 * SPDX-License-Identifier: LicenseRef-Nordic-5-Clause
 */

/ {
	/* Configure partition manager to use gd25lb256 as the external flash */
	chosen {
		nordic,pm-ext-flash = &gd25lb256;
	};
};

&gd25lb256 {
	status = "okay";
};
```

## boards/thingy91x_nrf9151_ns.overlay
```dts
/*
 * Copyright (c) 2024 Nordic Semiconductor ASA
 *
 * SPDX-License-Identifier: LicenseRef-Nordic-5-Clause
 */

#include <thingy91x_wifi.dtsi>

/ {
	aliases {
		temp-sensor = &bme680;
		ext-flash = &flash_ext;
	};

	chosen {
		zephyr,wifi = &nordic_wlan0;
	};
};

&bme680 {
	status = "okay";
};

/* Switch to nrf7000 emulation so that scan-only mode is used. */
&nrf70 {
	compatible = "nordic,nrf7000-spi";
};
```

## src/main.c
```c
/* Copyright (c) 2023 Nordic Semiconductor ASA
 *
 * SPDX-License-Identifier: LicenseRef-Nordic-5-Clause
 */

#include <zephyr/kernel.h>
#include <stdio.h>
#include <zephyr/logging/log.h>
#include "application.h"
#include "cloud_connection.h"
#include "message_queue.h"
#include "led_control.h"
#include "fota_support_coap.h"
#include "shadow_support_coap.h"

LOG_MODULE_REGISTER(main, CONFIG_MULTI_SERVICE_LOG_LEVEL);

/* Here, we start the various threads that our application will run in */

#ifndef CONFIG_LED_INDICATION_DISABLED
/* Define, and automatically start the LED animation thread. See led_control.c */
K_THREAD_DEFINE(led_thread, CONFIG_LED_THREAD_STACK_SIZE, led_animation_thread_fn,
		NULL, NULL, NULL, 0, 0, 0);
#endif

/* Define, and automatically start the main application thread. See application.c */
K_THREAD_DEFINE(app_thread, CONFIG_APPLICATION_THREAD_STACK_SIZE, main_application_thread_fn,
		NULL, NULL, NULL, 0, 0, 0);

/* Define, and automatically start the message queue thread. See message_queue.c */
K_THREAD_DEFINE(msg_thread, CONFIG_MESSAGE_THREAD_STACK_SIZE, message_queue_thread_fn,
		NULL, NULL, NULL, 0, 0, 0);

/* Define, and automatically start the cloud connection thread. See cloud_connection.c */
K_THREAD_DEFINE(con_thread, CONFIG_CONNECTION_THREAD_STACK_SIZE, cloud_connection_thread_fn,
		NULL, NULL, NULL, 0, 0, 0);

#if defined(CONFIG_NRF_CLOUD_COAP)
#if defined(CONFIG_COAP_FOTA)
/* Define, and automatically start the CoAP FOTA check thread. See fota_support_coap.c */
K_THREAD_DEFINE(coap_fota, CONFIG_COAP_FOTA_THREAD_STACK_SIZE, coap_fota_thread_fn,
		NULL, NULL, NULL, 0, 0, 0);
#endif

#if defined(CONFIG_COAP_SHADOW)
/* Define, and automatically start the CoAP shadow check thread. See shadow_support_coap.c */
K_THREAD_DEFINE(coap_shadow, CONFIG_COAP_SHADOW_THREAD_STACK_SIZE, coap_shadow_thread_fn,
		NULL, NULL, NULL, 0, 0, 0);
#endif
#endif /* CONFIG_NRF_CLOUD_COAP */

/* main() is called from the main thread, which defaults to priority zero,
 * but for illustrative purposes we don't use it. main_application() could be called directly
 * from this function, rather than given its own dedicated thread.
 */
int main(void)
{
	const char *protocol;

	if (IS_ENABLED(CONFIG_NRF_CLOUD_MQTT)) {
		protocol = "MQTT";
	} else if (IS_ENABLED(CONFIG_NRF_CLOUD_COAP)) {
		protocol = "CoAP";
	}

	LOG_INF("nRF Cloud multi-service sample has started, version: %s, protocol: %s",
		CONFIG_APP_VERSION, protocol);

	return 0;
}
```

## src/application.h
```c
/* Copyright (c) 2023 Nordic Semiconductor ASA
 *
 * SPDX-License-Identifier: LicenseRef-Nordic-5-Clause
 */

#ifndef _APPLICATION_H_
#define _APPLICATION_H_

#if defined(CONFIG_NRF_CLOUD_MQTT)
#define MSG_OBJ_DEFINE(_obj_name) \
	NRF_CLOUD_OBJ_JSON_DEFINE(_obj_name);
#elif defined(CONFIG_NRF_CLOUD_COAP)
#define MSG_OBJ_DEFINE(_obj_name) \
	NRF_CLOUD_OBJ_COAP_CBOR_DEFINE(_obj_name);
#endif

/**
 * @brief Main application -- Wait for valid connection, start location tracking, and then
 * periodically sample sensors and send them to nRF Cloud.
 */
void main_application_thread_fn(void);

#endif /* _APPLICATION_H_ */
```

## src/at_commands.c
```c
/* Copyright (c) 2023 Nordic Semiconductor ASA
 *
 * SPDX-License-Identifier: LicenseRef-Nordic-5-Clause
 */

#include <zephyr/kernel.h>
#include <zephyr/logging/log.h>
#include <nrf_modem_at.h>
#include <nrf_errno.h>
#include <cJSON.h>
#include <stdio.h>

#include "nrf_cloud_codec_internal.h"
#include "cloud_connection.h"
#include "at_commands.h"

LOG_MODULE_REGISTER(at_cmd_execution, CONFIG_MULTI_SERVICE_LOG_LEVEL);

/* AT command request error handling */
#define AT_CMD_REQUEST_ERR_FORMAT "Error while processing AT command request: %d"
#define AT_CMD_REQUEST_ERR_MAX_LEN (sizeof(AT_CMD_REQUEST_ERR_FORMAT) + 20)
BUILD_ASSERT(CONFIG_AT_CMD_REQUEST_RESPONSE_BUFFER_LENGTH >= AT_CMD_REQUEST_ERR_MAX_LEN,
	     "Not enough AT command response buffer for printing error events.");

/* Buffer to contain modem responses when performing AT command requests */
static char at_cmd_resp_buf[CONFIG_AT_CMD_REQUEST_RESPONSE_BUFFER_LENGTH];

char *execute_at_cmd_request(const char *const cmd)
{
	LOG_DBG("Modem AT command requested: %s", cmd);

	/* Clear the response buffer */
	memset(at_cmd_resp_buf, 0, sizeof(at_cmd_resp_buf));

	/* Pass the command off to the modem.
	 *
	 * We must pass the command in using a format specifier it might contain special characters
	 * such as %.
	 *
	 * We subtract 1 from the passed-in response buffer length to ensure that the response is
	 * always null-terminated, even when the response is longer than the response buffer size.
	 */

	int err = nrf_modem_at_cmd(at_cmd_resp_buf, sizeof(at_cmd_resp_buf) - 1, "%s", cmd);

	/* Post-process the response */
	LOG_DBG("Modem AT command response (%d, %d): %s",
		nrf_modem_at_err_type(err), nrf_modem_at_err(err), at_cmd_resp_buf);

	/* Trim \r\n from modem response for better readability in the portal. */
	at_cmd_resp_buf[MAX(0, strlen(at_cmd_resp_buf) - 2)] = '\0';

	/* If an error occurred with the request, report it */
	if (err < 0) {
		/* Negative error codes indicate an error with the modem lib itself, so the
		 * response buffer will be empty (or filled with junk). Thus, we can print the
		 * error message directly into it.
		 */
		snprintf(at_cmd_resp_buf, sizeof(at_cmd_resp_buf), AT_CMD_REQUEST_ERR_FORMAT, err);
		LOG_ERR("%s", at_cmd_resp_buf);
	}

	/* Return a pointer to the start of the command response buffer (which is now populated with
	 * the AT command response)
	 */
	return &at_cmd_resp_buf[0];
}
```

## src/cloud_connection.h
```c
/* Copyright (c) 2023 Nordic Semiconductor ASA
 *
 * SPDX-License-Identifier: LicenseRef-Nordic-5-Clause
 */

#ifndef _CLOUD_CONNECTION_H_
#define _CLOUD_CONNECTION_H_
#include <net/nrf_cloud.h>

/**
 * @brief nRF Cloud device message handler.
 *
 * @param[in] dev_msg The received device message as a NULL-terminated string
 */
typedef void (*dev_msg_handler_cb_t)(const struct nrf_cloud_data *const dev_msg);

/**
 * @brief Sleep until the network is ready for use, or the specified timeout elapses.
 *
 * @param timeout - The time to wait before timing out.
 * @return true if the network became ready in time.
 * @return false if timed out.
 */
bool await_network_ready(k_timeout_t timeout);

/**
 * @brief Sleep until the nRF Cloud connection is ready for use, or the specified timeout elapses.
 *
 * @param timeout - The time to wait before timing out.
 * @return true if nRF Cloud became ready in time.
 * @return false if timed out.
 */
bool await_cloud_ready(k_timeout_t timeout);

/**
 * @brief Sleep until connection to nRF Cloud is lost, or the specified timeout elapses.
 *
 * @param timeout - The time to wait before timing out.
 * @return true if the connection was lost within the timeout.
 * @return false if timed out.
 */
bool await_cloud_disconnected(k_timeout_t timeout);

/**
 * @brief Sleep until the current date-time is known, or the specified timeout elapses.
 *
 * @param timeout - The time to wait before timing out.
 * @return true if the current date-time was determined within the timeout.
 * @return false if timed out.
 */
bool await_date_time_known(k_timeout_t timeout);

/**
 * @brief Check if device has been removed from the cloud.
 *
 * @return true if it was just removed.
 * @return false if not removed.
 */
bool is_device_deleted(void);

/**
 * @brief Register a device message handler to receive general device messages from nRF Cloud.
 *
 * The callback will be called directly from the nRF Cloud connection poll thread, so it will block
 * receipt of data from nRF Cloud until complete. Avoid lengthy operations.
 *
 * @param handler_cb - The callback to handle device messages
 */
void register_general_dev_msg_handler(dev_msg_handler_cb_t handler_cb);

/**
 * @brief Disconnect from nRF Cloud and update internal state accordingly.
 *
 * May also be called to report an external disconnection.
 */
void disconnect_cloud(void);

/**
 * @brief Report a communications error so the cloud_connection can evaluate and
 * recover.
 */
void cloud_transport_error_detected(void);

/**
 * @brief Cloud connection thread function.
 *
 * This function manages the cloud connection thread. Once called, it begins monitoring network
 * status and persistently maintains a connection to nRF Cloud whenever Internet is available.
 */
void cloud_connection_thread_fn(void);

#endif /* _CLOUD_CONNECTION_H_ */
```

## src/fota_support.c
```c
/* Copyright (c) 2022 Nordic Semiconductor ASA
 *
 * SPDX-License-Identifier: LicenseRef-Nordic-5-Clause
 */

#include <zephyr/kernel.h>
#include <zephyr/logging/log.h>
#include <net/nrf_cloud.h>

#include "fota_support.h"
#include "sample_reboot.h"

LOG_MODULE_REGISTER(fota_support, CONFIG_MULTI_SERVICE_LOG_LEVEL);

void on_fota_downloaded(void)
{
	sample_reboot_normal();
}

struct dfu_target_fmfu_fdev *get_full_modem_fota_fdev(void)
{
	if (IS_ENABLED(CONFIG_NRF_CLOUD_FOTA_FULL_MODEM_UPDATE)) {
		static struct dfu_target_fmfu_fdev ext_flash_dev = {
			.size = 0,
			.offset = 0,
			/* CONFIG_DFU_TARGET_FULL_MODEM_USE_EXT_PARTITION is enabled,
			 * so no need to specify the flash device here
			 */
			.dev = NULL
		};

		return &ext_flash_dev;
	}

	return NULL;
}

/* You may notice there is no logic to actually receive/download/apply FOTA updates.
 * That is because these features are automatically implemented for MQTT by enabling
 * CONFIG_NRF_CLOUD_FOTA (which is implicitly enabled by CONFIG_NRF_CLOUD_MQTT).
 *
 * Note, also that connection.c is responsible for actually enabling FOTA in the nRF
 * Cloud portal, (by correctly updating the device shadow) as well as for notifying
 * fota_support.c of FOTA download completion.
 */
```

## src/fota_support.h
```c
/* Copyright (c) 2022 Nordic Semiconductor ASA
 *
 * SPDX-License-Identifier: LicenseRef-Nordic-5-Clause
 */

#ifndef _FOTA_SUPPORT_H_
#define _FOTA_SUPPORT_H_

#include <zephyr/kernel.h>

/* Time in seconds to wait before rebooting after a FOTA update. */
#define FOTA_REBOOT_DELAY_S	5
#define PENDING_REBOOT_S	10
#define ERROR_REBOOT_S		30
#define FOTA_REBOOT_S		10

/**
 * @brief Notify fota_support that a FOTA download has finished.
 *
 * Besides updating the device shadow (handled in connection.c), this is the only additional
 * code needed to get FOTA working properly, and its sole function is to reboot the microcontroller
 * after FOTA download completes.
 *
 */
void on_fota_downloaded(void);

/**
 * @brief Get the external flash device used for full modem FOTA updates.
 *
 * This function returns NULL if CONFIG_NRF_CLOUD_FOTA_FULL_MODEM_UPDATE is not
 * enabled.
 *
 */
struct dfu_target_fmfu_fdev * get_full_modem_fota_fdev(void);

#endif /* _FOTA_SUPPORT_H_ */
```

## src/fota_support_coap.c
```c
/*
 * Copyright (c) 2023 Nordic Semiconductor ASA
 *
 * SPDX-License-Identifier: LicenseRef-Nordic-5-Clause
 */

#include <zephyr/kernel.h>
#include <modem/nrf_modem_lib.h>
#include <nrf_modem_at.h>
#include <zephyr/settings/settings.h>
#include <net/nrf_cloud.h>
#include <zephyr/logging/log.h>
#include <net/fota_download.h>
#include <net/nrf_cloud_coap.h>
#include <net/nrf_cloud_fota_poll.h>
#include "cloud_connection.h"
#include "fota_support.h"
#include "fota_support_coap.h"
#include "sample_reboot.h"

LOG_MODULE_REGISTER(fota_support_coap, CONFIG_MULTI_SERVICE_LOG_LEVEL);

#define FOTA_THREAD_DELAY_S 10

static void fota_reboot(enum nrf_cloud_fota_reboot_status status);

/* FOTA support context */
static struct nrf_cloud_fota_poll_ctx ctx = {
	.reboot_fn = fota_reboot
};

void fota_reboot(enum nrf_cloud_fota_reboot_status status)
{
	switch (status) {
	case FOTA_REBOOT_REQUIRED:
		sample_reboot_normal();
		break;
	case FOTA_REBOOT_SUCCESS:
		LOG_INF("Rebooting to complete FOTA update...");
		sample_reboot_normal();
		break;
	case FOTA_REBOOT_FAIL:
	case FOTA_REBOOT_SYS_ERROR:
	default:
		sample_reboot_error();
		break;
	}
}

int coap_fota_init(void)
{
	int err = nrf_cloud_fota_poll_init(&ctx);

	if (err) {
		return err;
	}

	/* Process pending FOTA job, the FOTA type is returned */
	err = nrf_cloud_fota_poll_process_pending(&ctx);
	if (err < 0) {
		return err;
	} else if (err != NRF_CLOUD_FOTA_TYPE__INVALID) {
		LOG_INF("Processed pending FOTA job type: %d", err);
	}

	return 0;
}

int coap_fota_thread_fn(void)
{
	int err;

	while (1) {
		/* Wait until we are able to communicate. */
		LOG_DBG("Waiting for valid connection before processing FOTA");
		(void)await_cloud_ready(K_FOREVER);

		/* Query for any queued FOTA jobs. If one is found, download and install
		 * it. This is a blocking operation which can take a long time.
		 * This function is likely to reboot in order to complete the FOTA update.
		 */
		err = nrf_cloud_fota_poll_process(&ctx);
		if (err == -EAGAIN) {
			LOG_INF("Checking for FOTA job in %d seconds",
				CONFIG_COAP_FOTA_JOB_CHECK_RATE_MINUTES * SEC_PER_MIN);
			k_sleep(K_MINUTES(CONFIG_COAP_FOTA_JOB_CHECK_RATE_MINUTES));
			continue;
		}
		if (err == -ENOENT) {
			cloud_transport_error_detected();
		}
		k_sleep(K_SECONDS(FOTA_THREAD_DELAY_S));
	}
	return 0;
}
```

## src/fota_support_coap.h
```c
/*
 * Copyright (c) 2023 Nordic Semiconductor ASA
 *
 * SPDX-License-Identifier: LicenseRef-Nordic-5-Clause
 */

#ifndef FOTA_SUPPORT_COAP_H
#define FOTA_SUPPORT_COAP_H

int coap_fota_init(void);
int coap_fota_begin(void);

int coap_fota_thread_fn(void);

#endif /* FOTA_SUPPORT_COAP_H */
```
